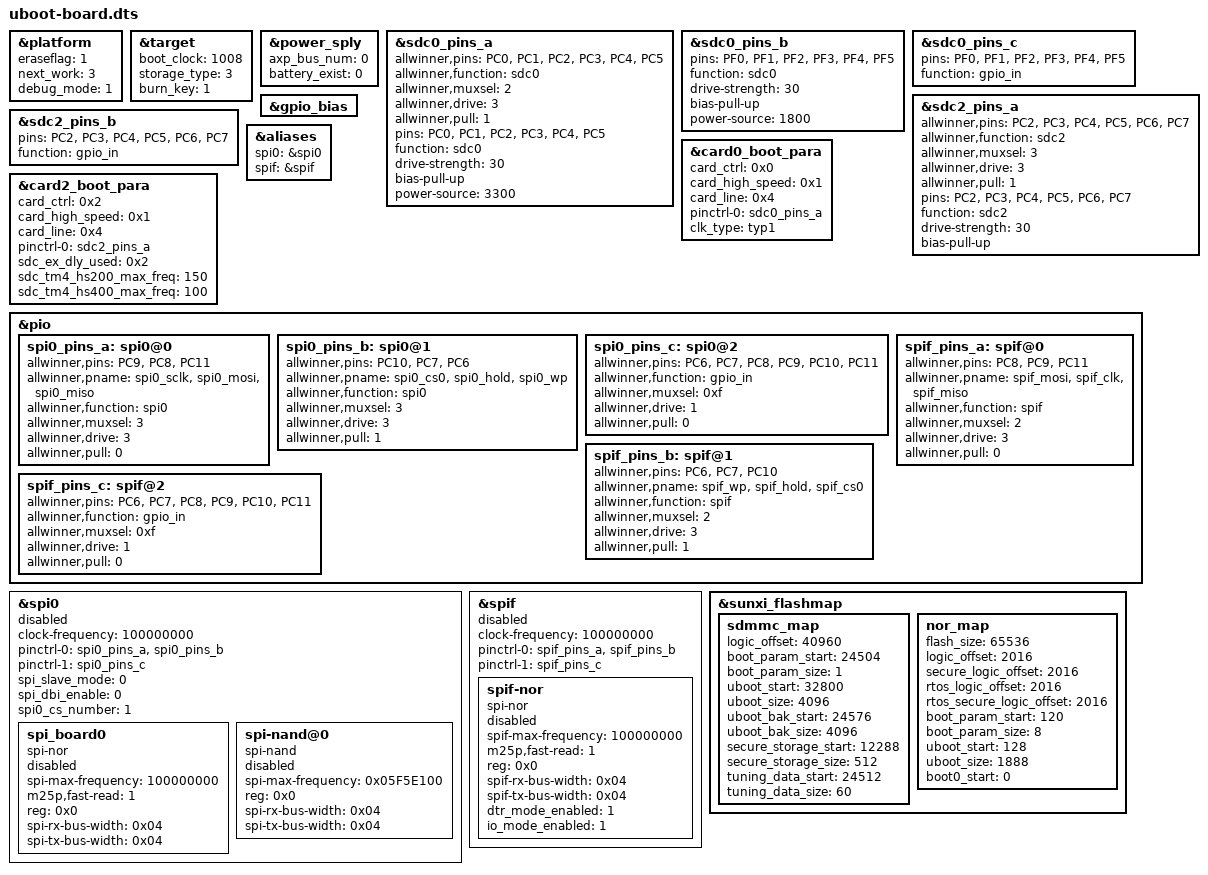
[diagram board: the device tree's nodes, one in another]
/*
* Allwinner Technology CO., Ltd. sun300iw1p1 soc board.
*
* soc board support.
*/

&platform {
	eraseflag   = <1>;
	next_work   = <3>;
	debug_mode  = <1>;
};

&target {
	boot_clock = <1008>;	/*CPU boot frequency, Unit: MHz*/
	storage_type = <3>; /*boot medium, 0-nand, 1-card0, 2-card2, 3-nor, -1(defualt)auto scan*/
	burn_key = <1>;		/*1:support burn key; 0:not support burn key*/
};

&power_sply {
	axp_bus_num	= <0>;
	battery_exist = <0>;
};

&sdc0_pins_a {
	allwinner,pins = "PC0", "PC1", "PC2",
			"PC3", "PC4", "PC5";
	allwinner,function = "sdc0";
	allwinner,muxsel = <2>;
	allwinner,drive = <3>;
	allwinner,pull = <1>;
	pins = "PC0", "PC1", "PC2",
		"PC3", "PC4", "PC5";
	function = "sdc0";
	drive-strength = <30>;
	bias-pull-up;
	power-source = <3300>;
};

&sdc0_pins_b {
	pins = "PF0", "PF1", "PF2",
		"PF3", "PF4", "PF5";
	function = "sdc0";
	drive-strength = <30>;
	bias-pull-up;
	power-source = <1800>;
};

&sdc0_pins_c {
	pins = "PF0", "PF1", "PF2",
		"PF3", "PF4", "PF5";
	function = "gpio_in";
};

&sdc2_pins_a {
	allwinner,pins = "PC2", "PC3", "PC4",
			"PC5", "PC6", "PC7";
	allwinner,function = "sdc2";
	allwinner,muxsel = <3>;
	allwinner,drive = <3>;
	allwinner,pull = <1>;
	pins = "PC2", "PC3", "PC4",
		"PC5", "PC6", "PC7";
	function = "sdc2";
	drive-strength = <30>;
	bias-pull-up;

};

&sdc2_pins_b {
	pins = "PC2", "PC3", "PC4",
		"PC5", "PC6", "PC7";
	function = "gpio_in";
};

&card0_boot_para {  /* Avoid dtc compiling warnings. @TODO: Developer should modify this to the actual value */
	/* reg = <0x0 0x2 0x0 0x0>;  [> Avoid dtc compiling warnings. @TODO: Developer should modify this to the actual value <] */
	device_type = "card0_boot_para";
	card_ctrl = <0x0>;
	card_high_speed = <0x1>;
	card_line = <0x4>;
	pinctrl-0 = <&sdc0_pins_a>;
	clk_type = "typ1";
};

&card2_boot_para {  /* Avoid dtc compiling warnings. @TODO: Developer should modify this to the actual value */
	/* reg = <0x0 0x3 0x0 0x0>;  [> Avoid dtc compiling warnings. @TODO: Developer should modify this to the actual value <] */
	device_type = "card2_boot_para";
	card_ctrl = <0x2>;
	card_high_speed = <0x1>;
	card_line = <0x4>;
	pinctrl-0 = <&sdc2_pins_a>;
	sdc_ex_dly_used = <0x2>;
	sdc_tm4_hs200_max_freq = <150>;
	sdc_tm4_hs400_max_freq = <100>;
};

&gpio_bias {  /* Avoid dtc compiling warnings. @TODO: Developer should modify this to the actual value */
	device_type = "gpio_bias";
};

&aliases {
	spi0 = &spi0;
	spif = &spif;
};

&pio{
	spi0_pins_a: spi0@0 {
		allwinner,pins = "PC9", "PC8", "PC11";
		allwinner,pname = "spi0_sclk", "spi0_mosi",
				"spi0_miso";
		allwinner,function = "spi0";
		allwinner,muxsel = <3>;
		allwinner,drive = <3>;
		allwinner,pull = <0>;
	};

	spi0_pins_b: spi0@1 {
		allwinner,pins = "PC10", "PC7", "PC6";
		allwinner,pname = "spi0_cs0", "spi0_hold",
				"spi0_wp";
		allwinner,function = "spi0";
		allwinner,muxsel = <3>;
		allwinner,drive = <3>;
		allwinner,pull = <1>;   // only CS should be pulled up
	};

	spi0_pins_c: spi0@2 {
		allwinner,pins = "PC6", "PC7", "PC8", "PC9",
				"PC10", "PC11";
		allwinner,function = "gpio_in";
		allwinner,muxsel = <0xf>;
		allwinner,drive = <1>;
		allwinner,pull = <0>;
	};

	spif_pins_a: spif@0 {
		allwinner,pins = "PC8", "PC9", "PC11";
		allwinner,pname = "spif_mosi", "spif_clk", "spif_miso";
		allwinner,function = "spif";
		allwinner,muxsel = <2>;
		allwinner,drive = <3>;
		allwinner,pull = <0>;
	};

	spif_pins_b: spif@1 {
		allwinner,pins = "PC6", "PC7", "PC10";
		allwinner,pname = "spif_wp", "spif_hold", "spif_cs0";
		allwinner,function = "spif";
		allwinner,muxsel = <2>;
		allwinner,drive = <3>;
		allwinner,pull = <1>;   // only CS should be pulled up
	};

	spif_pins_c: spif@2 {
		allwinner,pins = "PC6", "PC7", "PC8", "PC9", "PC10", "PC11";
		allwinner,function = "gpio_in";
		allwinner,muxsel = <0xf>;
		allwinner,drive = <1>;
		allwinner,pull = <0>;
	};
};

&spi0 {
	clock-frequency = <100000000>;
	pinctrl-0 = <&spi0_pins_a &spi0_pins_b>;
	pinctrl-1 = <&spi0_pins_c>;
	pinctrl-names = "default", "sleep";
	spi_slave_mode = <0>;
	spi_dbi_enable = <0>;
	spi0_cs_number = <1>;
	status = "disabled";

	spi_board0 {
		device_type = "spi_board0";
		compatible = "spi-nor";
		spi-max-frequency = <100000000>;
		m25p,fast-read = <1>;
		/*individual_lock;*/
		reg = <0x0>;
		spi-rx-bus-width=<0x04>;
		spi-tx-bus-width=<0x04>;
		status="disabled";
	};

	spi-nand@0 {
		compatible = "spi-nand";
		spi-max-frequency=<0x05F5E100>;
		reg = <0x0>;
		spi-rx-bus-width=<0x04>;
		spi-tx-bus-width=<0x04>;
		status="disabled";
	};
};

&spif {
	clock-frequency = <100000000>;
	pinctrl-0 = <&spif_pins_a &spif_pins_b>;
	pinctrl-1 = <&spif_pins_c>;
	pinctrl-names = "default", "sleep";
	/*spi-supply = <&reg_dcdc1>;*/
	status = "disabled";

	spif-nor {
		device_type = "spi_board0";
		compatible = "spi-nor";
		spif-max-frequency = <100000000>;
		m25p,fast-read = <1>;
		/*individual_lock;*/
		reg = <0x0>;
		spif-rx-bus-width=<0x04>;
		spif-tx-bus-width=<0x04>;
		dtr_mode_enabled=<1>;	/* choose double edge trigger mode */
		io_mode_enabled=<1>;	/* 1_x_x && x_x_x mode */
		status="disabled";
	};
};

&sunxi_flashmap {
	/* Unit: Sector */
	sdmmc_map {
		logic_offset = <40960>;
		boot_param_start = <24504>;
		boot_param_size = <1>;
		uboot_start = <32800>;
		uboot_size = <4096>;
		uboot_bak_start = <24576>;
		uboot_bak_size = <4096>;
		secure_storage_start = <12288>;
		secure_storage_size = <512>;
		tuning_data_start = <24512>;
		tuning_data_size = <60>;
		status = "okay";
	};

	nor_map {
		/*Unit: Sector, 8M flash:16384, 16M flash:32768, 32M flash:65536*/
		/* logic offset requires block size(64K) alignment - 32(mbr size) */
		flash_size = <65536>;
		logic_offset = <2016>;
		secure_logic_offset = <2016>;
		rtos_logic_offset = <2016>;
		rtos_secure_logic_offset = <2016>;
		boot_param_start = <120>;
		boot_param_size = <8>;
		uboot_start = <128>;
		uboot_size = <1888>;
		boot0_start = <0>;
		status = "okay";
	};
};
